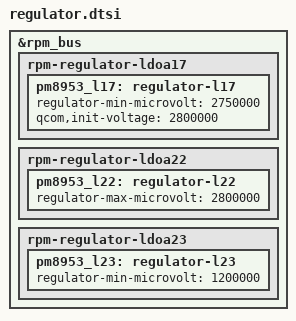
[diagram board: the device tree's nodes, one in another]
/* msm8953-regulator */
&rpm_bus {
	rpm-regulator-ldoa17 {
		pm8953_l17: regulator-l17 {
			regulator-min-microvolt = <2750000>;
			qcom,init-voltage = <2800000>;
		};
	};

	rpm-regulator-ldoa22 {
		pm8953_l22: regulator-l22 {
			regulator-max-microvolt = <2800000>;
		};
	};

	rpm-regulator-ldoa23 {
		pm8953_l23: regulator-l23 {
			regulator-min-microvolt = <1200000>;
		};
	};
}; 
